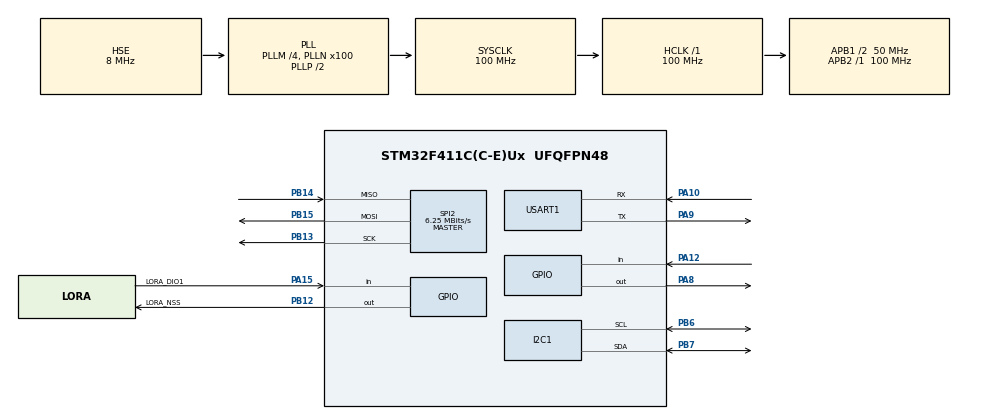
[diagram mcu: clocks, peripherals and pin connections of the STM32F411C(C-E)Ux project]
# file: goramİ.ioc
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Mcu.Family=STM32F4
Mcu.Name=STM32F411C(C-E)Ux
Mcu.Package=UFQFPN48
NVIC.PriorityGroup=NVIC_PRIORITYGROUP_4
NVIC.USART1_IRQn=true\:0\:0\:false\:false\:true\:true\:true\:true
PA10.Mode=Asynchronous
PA10.Signal=USART1_RX
PA12.Signal=GPIO_Input
PA13.Mode=Serial_Wire
PA13.Signal=SYS_JTMS-SWDIO
PA14.Mode=Serial_Wire
PA14.Signal=SYS_JTCK-SWCLK
PA15.GPIO_Label=LORA_DIO1
PA15.Signal=GPIO_Input
PA8.Signal=GPIO_Output
PA9.Mode=Asynchronous
PA9.Signal=USART1_TX
PB12.GPIO_Label=LORA_NSS
PB12.Signal=GPIO_Output
PB13.Mode=Full_Duplex_Master
PB13.Signal=SPI2_SCK
PB14.Mode=Full_Duplex_Master
PB14.Signal=SPI2_MISO
PB15.Mode=Full_Duplex_Master
PB15.Signal=SPI2_MOSI
PB6.Mode=I2C
PB6.Signal=I2C1_SCL
PB7.Mode=I2C
PB7.Signal=I2C1_SDA
PH0\ -\ OSC_IN.Mode=HSE-External-Oscillator
PH0\ -\ OSC_IN.Signal=RCC_OSC_IN
PH1\ -\ OSC_OUT.Mode=HSE-External-Oscillator
PH1\ -\ OSC_OUT.Signal=RCC_OSC_OUT
ProjectManager.HeapSize=0x200
ProjectManager.StackSize=0x400
ProjectManager.TargetToolchain=STM32CubeIDE
RCC.48MHZClocksFreq_Value=50000000
RCC.AHBFreq_Value=100000000
RCC.APB1CLKDivider=RCC_HCLK_DIV2
RCC.APB1Freq_Value=50000000
RCC.APB1TimFreq_Value=100000000
RCC.APB2Freq_Value=100000000
RCC.APB2TimFreq_Value=100000000
RCC.CortexFreq_Value=100000000
RCC.HCLKFreq_Value=100000000
RCC.HSE_VALUE=8000000
RCC.HSI_VALUE=16000000
RCC.LSE_VALUE=32768
RCC.PLLM=4
RCC.PLLN=100
RCC.PLLSourceVirtual=RCC_PLLSOURCE_HSE
RCC.SYSCLKFreq_VALUE=100000000
RCC.SYSCLKSource=RCC_SYSCLKSOURCE_PLLCLK
RCC.VCOOutputFreq_Value=200000000
SPI2.BaudRatePrescaler=SPI_BAUDRATEPRESCALER_8
SPI2.CalculateBaudRate=6.25 MBits/s
SPI2.Direction=SPI_DIRECTION_2LINES
SPI2.Mode=SPI_MODE_MASTER
SPI2.VirtualType=VM_MASTER
USART1.VirtualMode=VM_ASYNC
board=custom

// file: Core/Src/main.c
/* USER CODE BEGIN Header */
/**
  ******************************************************************************
  * @file           : main.c
  * @brief          : Main program body
  ******************************************************************************
  * @attention
  *
  * Copyright (c) 2026 STMicroelectronics.
  * All rights reserved.
  *
  * This software is licensed under terms that can be found in the LICENSE file
  * in the root directory of this software component.
  * If no LICENSE file comes with this software, it is provided AS-IS.
  *
  ******************************************************************************
  */
/* USER CODE END Header */
#include "main.h"

/* USER CODE BEGIN Includes */
#include "app/app.h"

/* USER CODE END Includes */

I2C_HandleTypeDef hi2c1;

SPI_HandleTypeDef hspi2;

UART_HandleTypeDef huart1;

void SystemClock_Config(void);
static void MX_GPIO_Init(void);
static void MX_I2C1_Init(void);
static void MX_SPI2_Init(void);
static void MX_USART1_UART_Init(void);

int main(void)
{

  /* MCU Configuration--------------------------------------------------------*/

  /* Reset of all peripherals, Initializes the Flash interface and the Systick. */
  HAL_Init();

  /* Configure the system clock */
  SystemClock_Config();

  /* Initialize all configured peripherals */
  MX_GPIO_Init();
  MX_I2C1_Init();
  MX_SPI2_Init();
  MX_USART1_UART_Init();
  /* USER CODE BEGIN 2 */
  if (!App_Init(&hi2c1, &hspi2, &huart1)) {
    Error_Handler();
  }

  /* USER CODE END 2 */

  /* Infinite loop */
  while (1)
  {

    /* USER CODE BEGIN 3 */
    App_Run();
  }
  /* USER CODE END 3 */
}

void SystemClock_Config(void)
{
  RCC_OscInitTypeDef RCC_OscInitStruct = {0};
  RCC_ClkInitTypeDef RCC_ClkInitStruct = {0};

  /** Configure the main internal regulator output voltage
  */
  __HAL_RCC_PWR_CLK_ENABLE();
  __HAL_PWR_VOLTAGESCALING_CONFIG(PWR_REGULATOR_VOLTAGE_SCALE1);

  /** Initializes the RCC Oscillators according to the specified parameters
  * in the RCC_OscInitTypeDef structure.
  */
  RCC_OscInitStruct.OscillatorType = RCC_OSCILLATORTYPE_HSE;
  RCC_OscInitStruct.HSEState = RCC_HSE_ON;
  RCC_OscInitStruct.PLL.PLLState = RCC_PLL_ON;
  RCC_OscInitStruct.PLL.PLLSource = RCC_PLLSOURCE_HSE;
  RCC_OscInitStruct.PLL.PLLM = 4;
  RCC_OscInitStruct.PLL.PLLN = 100;
  RCC_OscInitStruct.PLL.PLLP = RCC_PLLP_DIV2;
  RCC_OscInitStruct.PLL.PLLQ = 4;
  if (HAL_RCC_OscConfig(&RCC_OscInitStruct) != HAL_OK)
  {
    Error_Handler();
  }

  /** Initializes the CPU, AHB and APB buses clocks
  */
  RCC_ClkInitStruct.ClockType = RCC_CLOCKTYPE_HCLK|RCC_CLOCKTYPE_SYSCLK
                              |RCC_CLOCKTYPE_PCLK1|RCC_CLOCKTYPE_PCLK2;
  RCC_ClkInitStruct.SYSCLKSource = RCC_SYSCLKSOURCE_PLLCLK;
  RCC_ClkInitStruct.AHBCLKDivider = RCC_SYSCLK_DIV1;
  RCC_ClkInitStruct.APB1CLKDivider = RCC_HCLK_DIV2;
  RCC_ClkInitStruct.APB2CLKDivider = RCC_HCLK_DIV1;

  if (HAL_RCC_ClockConfig(&RCC_ClkInitStruct, FLASH_LATENCY_3) != HAL_OK)
  {
    Error_Handler();
  }
}

static void MX_I2C1_Init(void)
{

  hi2c1.Instance = I2C1;
  hi2c1.Init.ClockSpeed = 100000;
  hi2c1.Init.DutyCycle = I2C_DUTYCYCLE_2;
  hi2c1.Init.OwnAddress1 = 0;
  hi2c1.Init.AddressingMode = I2C_ADDRESSINGMODE_7BIT;
  hi2c1.Init.DualAddressMode = I2C_DUALADDRESS_DISABLE;
  hi2c1.Init.OwnAddress2 = 0;
  hi2c1.Init.GeneralCallMode = I2C_GENERALCALL_DISABLE;
  hi2c1.Init.NoStretchMode = I2C_NOSTRETCH_DISABLE;
  if (HAL_I2C_Init(&hi2c1) != HAL_OK)
  {
    Error_Handler();
  }

}

static void MX_SPI2_Init(void)
{

  /* SPI2 parameter configuration*/
  hspi2.Instance = SPI2;
  hspi2.Init.Mode = SPI_MODE_MASTER;
  hspi2.Init.Direction = SPI_DIRECTION_2LINES;
  hspi2.Init.DataSize = SPI_DATASIZE_8BIT;
  hspi2.Init.CLKPolarity = SPI_POLARITY_LOW;
  hspi2.Init.CLKPhase = SPI_PHASE_1EDGE;
  hspi2.Init.NSS = SPI_NSS_SOFT;
  hspi2.Init.BaudRatePrescaler = SPI_BAUDRATEPRESCALER_8;
  hspi2.Init.FirstBit = SPI_FIRSTBIT_MSB;
  hspi2.Init.TIMode = SPI_TIMODE_DISABLE;
  hspi2.Init.CRCCalculation = SPI_CRCCALCULATION_DISABLE;
  hspi2.Init.CRCPolynomial = 10;
  if (HAL_SPI_Init(&hspi2) != HAL_OK)
  {
    Error_Handler();
  }
  /* USER CODE BEGIN SPI2_Init 2 */
  hspi2.Init.BaudRatePrescaler = SPI_BAUDRATEPRESCALER_8;
  if (HAL_SPI_Init(&hspi2) != HAL_OK) {
    Error_Handler();
  }
  /* USER CODE END SPI2_Init 2 */

}

static void MX_USART1_UART_Init(void)
{

  huart1.Instance = USART1;
  huart1.Init.BaudRate = 115200;
  huart1.Init.WordLength = UART_WORDLENGTH_8B;
  huart1.Init.StopBits = UART_STOPBITS_1;
  huart1.Init.Parity = UART_PARITY_NONE;
  huart1.Init.Mode = UART_MODE_TX_RX;
  huart1.Init.HwFlowCtl = UART_HWCONTROL_NONE;
  huart1.Init.OverSampling = UART_OVERSAMPLING_16;
  if (HAL_UART_Init(&huart1) != HAL_OK)
  {
    Error_Handler();
  }

}

static void MX_GPIO_Init(void)
{
  GPIO_InitTypeDef GPIO_InitStruct = {0};

  /* GPIO Ports Clock Enable */
  __HAL_RCC_GPIOH_CLK_ENABLE();
  __HAL_RCC_GPIOB_CLK_ENABLE();
  __HAL_RCC_GPIOA_CLK_ENABLE();

  /*Configure GPIO pin Output Level */
  HAL_GPIO_WritePin(LORA_NSS_GPIO_Port, LORA_NSS_Pin, GPIO_PIN_RESET);

  /*Configure GPIO pin Output Level */
  HAL_GPIO_WritePin(GPIOA, GPIO_PIN_8, GPIO_PIN_RESET);

  /*Configure GPIO pin : LORA_NSS_Pin */
  GPIO_InitStruct.Pin = LORA_NSS_Pin;
  GPIO_InitStruct.Mode = GPIO_MODE_OUTPUT_PP;
  GPIO_InitStruct.Pull = GPIO_NOPULL;
  GPIO_InitStruct.Speed = GPIO_SPEED_FREQ_LOW;
  HAL_GPIO_Init(LORA_NSS_GPIO_Port, &GPIO_InitStruct);

  /*Configure GPIO pin : PA8 */
  GPIO_InitStruct.Pin = GPIO_PIN_8;
  GPIO_InitStruct.Mode = GPIO_MODE_OUTPUT_PP;
  GPIO_InitStruct.Pull = GPIO_NOPULL;
  GPIO_InitStruct.Speed = GPIO_SPEED_FREQ_LOW;
  HAL_GPIO_Init(GPIOA, &GPIO_InitStruct);

  /*Configure GPIO pins : PA12 LORA_DIO1_Pin */
  GPIO_InitStruct.Pin = GPIO_PIN_12|LORA_DIO1_Pin;
  GPIO_InitStruct.Mode = GPIO_MODE_INPUT;
  GPIO_InitStruct.Pull = GPIO_NOPULL;
  HAL_GPIO_Init(GPIOA, &GPIO_InitStruct);

}

void Error_Handler(void)
{
  __disable_irq();
  while (1)
  {
  }
}
